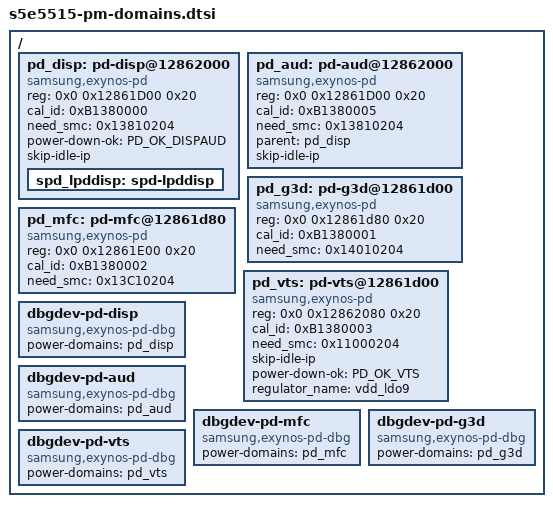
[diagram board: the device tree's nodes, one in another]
/*
 * SAMSUNG S5E5515 SoC PM Domains device tree source
 *
 * Copyright (c) 2021 Samsung Electronics Co., Ltd.
 *		http://www.samsung.com
 *
 * SAMSUNG S5E5515 SoC PM domains device nodes are listed in this file.
 * S5E5515 based board files can include this file and provide
 * values for board specfic bindings.
 *
 * This program is free software; you can redistribute it and/or modify
 * it under the terms of the GNU General Public License version 2 as
 * published by the Free Software Foundation.
 */
#include <dt-bindings/power/exynos-power.h>

/ {
	pd_disp: pd-disp@12862000 {
		compatible = "samsung,exynos-pd";
		reg = <0x0 0x12861D00 0x20>;
		cal_id = <0xB1380000>;
		need_smc = <0x13810204>;
		status = "okay";
		power-down-ok=<PD_OK_DISPAUD>;
		#power-domain-cells = <0>;
		skip-idle-ip;
		spd_lpddisp: spd-lpddisp {
			status = "okay";
			#power-domain-cells = <0>;
		};
	};

	pd_aud: pd-aud@12862000 {
		compatible = "samsung,exynos-pd";
		reg = <0x0 0x12861D00 0x20>;
		cal_id = <0xB1380005>;
		need_smc = <0x13810204>;
		status = "okay";
		parent = <&pd_disp>;
		#power-domain-cells = <0>;
		skip-idle-ip;
	};

	pd_g3d: pd-g3d@12861d00 {
		compatible = "samsung,exynos-pd";
		reg = <0x0 0x12861d80 0x20>;
		cal_id = <0xB1380001>;
		need_smc = <0x14010204>;
		status = "okay";
		#power-domain-cells = <0>;
	};

	pd_mfc: pd-mfc@12861d80 {
		compatible = "samsung,exynos-pd";
		reg = <0x0 0x12861E00 0x20>;
		cal_id = <0xB1380002>;
		need_smc = <0x13C10204>;
		status = "okay";
		#power-domain-cells = <0>;
	};

	pd_vts: pd-vts@12861d00 {
		compatible = "samsung,exynos-pd";
		reg = <0x0 0x12862080 0x20>;
		cal_id = <0xB1380003>;
		need_smc = <0x11000204>;
		status = "okay";
		skip-idle-ip;
		power-down-ok = <PD_OK_VTS>;
		#power-domain-cells = <0>;
		regulator_name = "vdd_ldo9";
	};

	dbgdev-pd-disp {
		compatible = "samsung,exynos-pd-dbg";
		power-domains = <&pd_disp>;
	};

	dbgdev-pd-aud {
		compatible = "samsung,exynos-pd-dbg";
		power-domains = <&pd_aud>;
	};

	dbgdev-pd-mfc {
		compatible = "samsung,exynos-pd-dbg";
		power-domains = <&pd_mfc>;
	};

	dbgdev-pd-g3d {
		compatible = "samsung,exynos-pd-dbg";
		power-domains = <&pd_g3d>;
	};

	dbgdev-pd-vts {
		compatible = "samsung,exynos-pd-dbg";
		power-domains = <&pd_vts>;
	};
};
